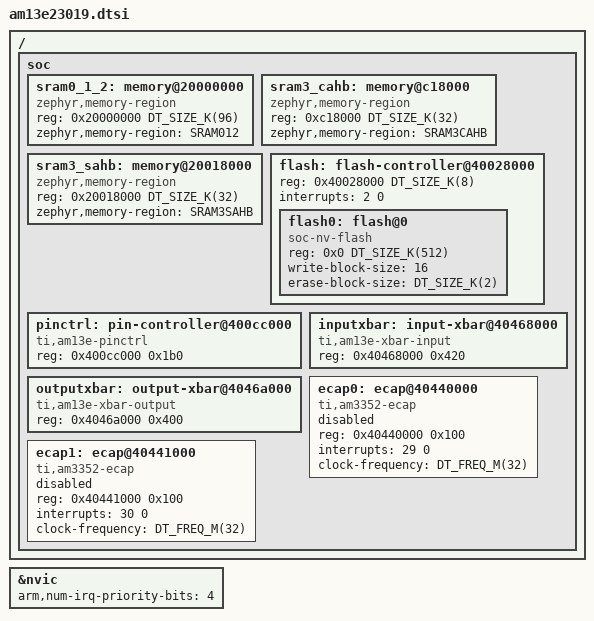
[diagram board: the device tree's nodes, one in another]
/*
 * Copyright (c) 2026 Texas Instruments Incorporated
 *
 * SPDX-License-Identifier: Apache-2.0
 */

#include "am13e.dtsi"

/ {
	#address-cells = <1>;
	#size-cells = <1>;

	soc {
		sram0_1_2: memory@20000000 {
			compatible = "zephyr,memory-region";
			reg = <0x20000000 DT_SIZE_K(96)>;
			zephyr,memory-region = "SRAM012";
		};

		sram3_cahb: memory@c18000 {
			compatible = "zephyr,memory-region";
			reg = <0xc18000 DT_SIZE_K(32)>;
			zephyr,memory-region = "SRAM3CAHB";
		};

		sram3_sahb: memory@20018000 {
			compatible = "zephyr,memory-region";
			reg = <0x20018000 DT_SIZE_K(32)>;
			zephyr,memory-region = "SRAM3SAHB";
		};

		flash: flash-controller@40028000 {
			reg = <0x40028000 DT_SIZE_K(8)>;
			ranges;
			interrupts = <2 0>;

			#address-cells = <1>;
			#size-cells = <1>;

			flash0: flash@0 {
				compatible = "soc-nv-flash";
				reg = <0x0 DT_SIZE_K(512)>;
				ranges = <0x0 0x0 DT_SIZE_K(512)>;

				write-block-size = <16>;
				erase-block-size = <DT_SIZE_K(2)>;

				#address-cells = <1>;
				#size-cells = <1>;
			};
		};

		pinctrl: pin-controller@400cc000 {
			compatible = "ti,am13e-pinctrl";
			reg = <0x400cc000 0x1b0>;
		};

		inputxbar: input-xbar@40468000 {
			compatible = "ti,am13e-xbar-input";
			reg = <0x40468000 0x420>;
			#mux-control-cells = <1>;
			#mux-state-cells = <2>;
		};

		outputxbar: output-xbar@4046a000 {
			compatible = "ti,am13e-xbar-output";
			reg = <0x4046a000 0x400>;
			#mux-control-cells = <1>;
			#mux-state-cells = <2>;
		};

		ecap0: ecap@40440000 {
			compatible = "ti,am3352-ecap";
			reg = <0x40440000 0x100>;
			interrupts = <29 0>;
			clock-frequency = <DT_FREQ_M(32)>;
			#pwm-cells = <3>;
			status = "disabled";
		};

		ecap1: ecap@40441000 {
			compatible = "ti,am3352-ecap";
			reg = <0x40441000 0x100>;
			interrupts = <30 0>;
			clock-frequency = <DT_FREQ_M(32)>;
			#pwm-cells = <3>;
			status = "disabled";
		};
	};
};

&nvic {
	arm,num-irq-priority-bits = <4>;
};
